# STM32N657 register map
File version: 1.0
CPU: CM55 r0p1, little endian, no MPU, FPU, vendor SysTick, 8 interrupt priority bits
Registers are 32-bit, read-write, reset 0x0 unless marked. A register's access mark holds for its fields unless they carry their own. Offsets are from the block's base; [hi:lo] are bit positions; {n}, {i} and the like mark numbered series.

## CRYP — Cryptographic processor
Base 0x44020800
Same registers: CRYP_S 0x54020800
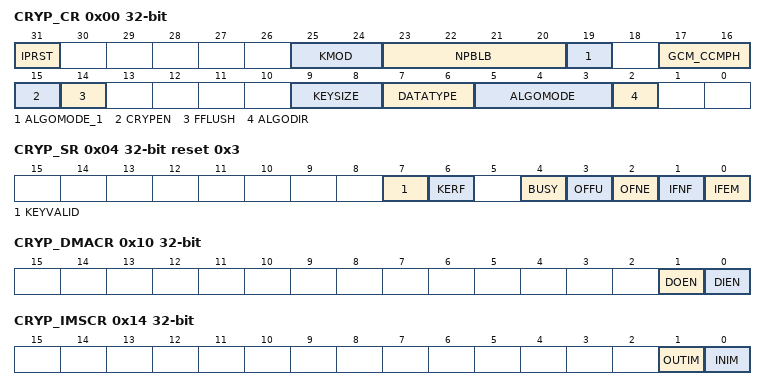
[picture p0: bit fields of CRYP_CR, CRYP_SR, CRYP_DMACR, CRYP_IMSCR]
0x00 CRYP_CR — CRYP control register
  [31] IPRST — CRYP peripheral software reset
  [25:24] KMOD — Key mode selection
    0=Normal-key mode. Key registers are freely usable.; 2=Shared-key mode. If shared-key mode is properly initialized in SAES peripheral, the CRYP peripheral automatically loads its key registers with the data stored in the SAES key registers. The key value is available in CRYP key registers when BUSY bit is cleared and KEYVALID is set in the CRYP_SR register. Key error flag KERF is set otherwise in the CRYP_SR register.
  [23:20] NPBLB — Number of padding bytes in last block
    0=All bytes are valid (no padding); 1=Padding for the last LSB byte; 15=Padding for the 15 LSB bytes of last block
  [19] ALGOMODE_1 — ALGOMODE[3]
  [17:16] GCM_CCMPH — GCM or CCM phase selection
    0=Initialization phase; 1=Header phase; 2=Payload phase; 3=Final phase
  [15] CRYPEN — CRYP enable
    0=CRYP disabled; 1=CRYP enabled
  [14] FFLUSH — FIFO flush
    0=No effect; 1=FIFO flush enabled
  [9:8] KEYSIZE — Key size selection
    0=128-bits; 1=192 bits; 2=256 bits
  [7:6] DATATYPE
    0=No swapping (32-bit data); 1=Half-word swapping (16-bit data); 2=Byte swapping (8-bit data); 3=Bit-level swapping
  [5:3] ALGOMODE — ALGOMODE[2:0]: Algorithm mode
    4=Electronic codebook (ECB); 5=Cipher Block Chaining (CBC); 6=Counter mode (CTR); 7=AES key preparation for ECB or CBC decryption
  [2] ALGODIR — Algorithm direction
    0=Encryption; 1=Decryption
0x04 CRYP_SR ro reset 0x3 — CRYP status register
  [7] KEYVALID — Key valid flag
    0=Key not valid; 1=Key valid
  [6] KERF — Key error flag
    0=No key error detected; 1=Key information failed to load into key registers
  [4] BUSY — Busy bit
    0=Idle; 1=Busy
  [3] OFFU — Output FIFO full flag
    0=Output FIFO is not full; 1=Output FIFO is full
  [2] OFNE — Output FIFO not empty flag
    0=Output FIFO is empty; 1=Output FIFO is not empty
  [1] IFNF — Input FIFO not full flag
    0=Input FIFO is full; 1=Input FIFO is not full
  [0] IFEM — Input FIFO empty flag
    0=Input FIFO is not empty; 1=Input FIFO is empty
0x08 CRYP_DINR — CRYP data input register
  [31:0] DIN — Data input
0x0C CRYP_DOUTR ro — CRYP data output register
  [31:0] DOUT — Data output
0x10 CRYP_DMACR — CRYP DMA control register
  [1] DOEN — DMA output enable
    0=Outgoing data transfer from CRYP via DMA is disabled; 1=Outgoing data transfer from CRYP via DMA is enabled
  [0] DIEN — DMA input enable
    0=Incoming data transfer to CRYP via DMA is disabled; 1=Incoming data transfer to CRYP via DMA is disabled
0x14 CRYP_IMSCR — CRYP interrupt mask set/clear register
  [1] OUTIM — Output FIFO service interrupt mask
    0=Output FIFO interrupt is disabled (masked), masked interrupt status (OUTMIS) stays cleared; 1=Output FIFO interrupt is enabled (not masked)
  [0] INIM — Input FIFO service interrupt mask
    0=Input FIFO interrupt is disabled (masked), masked interrupt status (INMIS) stays cleared; 1=Input FIFO interrupt is enabled (not masked)
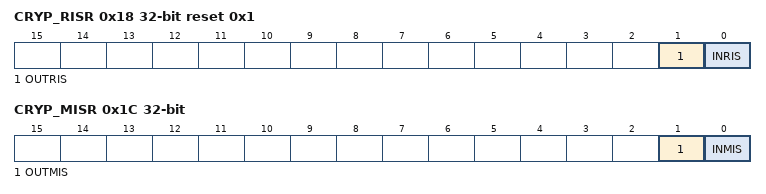
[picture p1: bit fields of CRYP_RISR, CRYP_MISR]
0x18 CRYP_RISR ro reset 0x1 — CRYP raw interrupt status register
  [1] OUTRIS — Output FIFO service raw interrupt status
    0=No output FIFO event detected; 1=Output FIFO full or not empty detected; an interrupt is generated if OUTIM bit is set in CRYP_IMSCR register
  [0] INRIS — Input FIFO service raw interrupt status
    0=No input FIFO event detected; 1=Input FIFO empty or not full detected; an interrupt is generated if CRYPEN is set and if INIM bit is set in CRYP_IMSCR register
0x1C CRYP_MISR ro — CRYP masked interrupt status register
  [1] OUTMIS — Output FIFO service masked interrupt status
    0=No output FIFO event detected or OUTIM mask cleared in CRYP_IMSCR; 1=Output FIFO full or not empty detected, with an interrupt pending
  [0] INMIS — Input FIFO service masked interrupt status
    0=No input FIFO event detected or INIM mask cleared in CRYP_IMSCR or CRYPEN bit cleared; 1=Input FIFO empty or not full detected, with an interrupt pending
{0x20+8i} CRYP_K{i}LR wo (i=0..3) — CRYP key register {i}L
  [31:0] K — Key bit x
{0x24+8i} CRYP_K{i}RR wo (i=0..3) — CRYP key register {i}R
  [31:0] K — Key bit x
0x40 CRYP_IV0LR — CRYP initialization vector register 0L
  [31:0] IVI — Initialization vector bit x
0x44 CRYP_IV0RR — CRYP initialization vector register 0R
  [31:0] IVI — Initialization vector bit x
0x48 CRYP_IV1LR — CRYP initialization vector register 1L
  [31:0] IVI — Initialization vector bit x
0x4C CRYP_IV1RR — CRYP initialization vector register 1R
  [31:0] IVI — Initialization vector bit x
{0x50+4i} CRYP_CSGCMCCM{i}R (i=0..7) — CRYP context swap GCM-CCM registers
  [31:0] CSGCMCCM — Context swap for GCM/GMAC and CCM modes
{0x70+4i} CRYP_CSGCM{i}R (i=0..7) — CRYP context swap GCM registers
  [31:0] CSGCM — Context swap for GCM/GMAC modes
